VERSION "1.0"

NS_ :

BS_:

BU_: ECM TCM Gateway

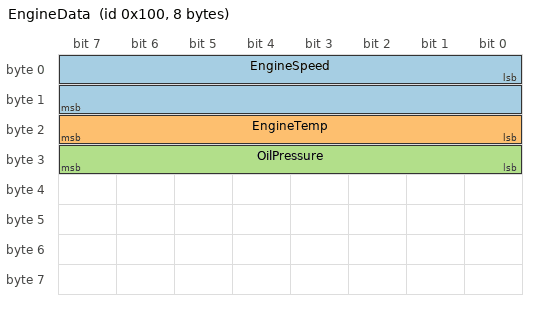
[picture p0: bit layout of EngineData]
BO_ 256 EngineData: 8 ECM
 SG_ EngineSpeed : 0|16@1+ (0.125,0) [0|8000] "rpm" TCM,Gateway
 SG_ EngineTemp : 16|8@1+ (1,-40) [-40|215] "degC" TCM
 SG_ OilPressure : 24|8@1+ (4,0) [0|1000] "kPa" Gateway

BO_ 512 VehicleSpeed: 8 TCM
 SG_ WheelSpeedFL : 0|16@1+ (0.01,0) [0|300] "km/h" Gateway
 SG_ WheelSpeedFR : 16|16@1+ (0.01,0) [0|300] "km/h" Gateway

BA_DEF_ BO_  "GenMsgCycleTime" INT 0 10000;
BA_DEF_ SG_  "GenSigStartValue" FLOAT 0 100000;
BA_DEF_DEF_  "GenMsgCycleTime" 0;
BA_DEF_DEF_  "GenSigStartValue" 0;

BA_ "GenMsgCycleTime" BO_ 256 10;
BA_ "GenMsgCycleTime" BO_ 512 20;
BA_ "GenSigStartValue" SG_ 256 EngineTemp 80;
